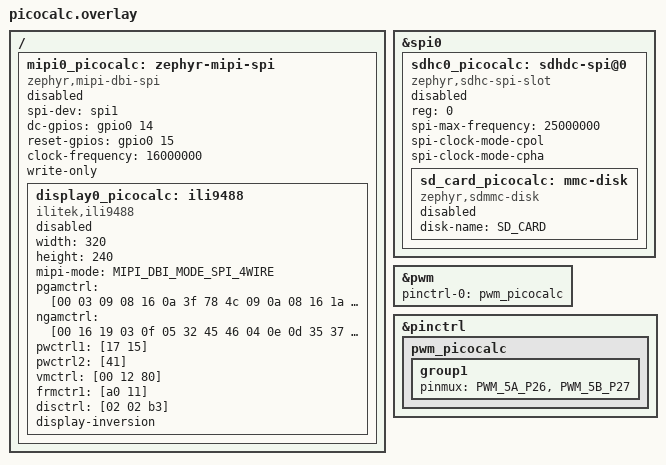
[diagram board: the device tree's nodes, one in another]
/ {
	mipi0_picocalc: zephyr-mipi-spi {
		compatible = "zephyr,mipi-dbi-spi";
		status = "disabled";

		spi-dev = <&spi1>;
		dc-gpios = <&gpio0 14 GPIO_ACTIVE_HIGH>;
		reset-gpios = <&gpio0 15 GPIO_ACTIVE_HIGH>;
		/* run at 16MHz */
		clock-frequency = <16000000>;
		write-only;

		display0_picocalc: ili9488 {
			compatible = "ilitek,ili9488";
			status = "disabled";

			width = <320>;
			height = <240>;
			mipi-mode = "MIPI_DBI_MODE_SPI_4WIRE";
			pgamctrl = [00 03 09 08 16 0a 3f 78 4c 09 0a 08 16 1a 0f];
			ngamctrl = [00 16 19 03 0f 05 32 45 46 04 0e 0d 35 37 0f];
			pwctrl1 = [17 15];
			pwctrl2 = [41];
			vmctrl = [00 12 80];

			frmctr1 = [a0 11];
			disctrl = [02 02 b3];

			display-inversion;
		};
	};
};

&spi0 {
	sdhc0_picocalc: sdhdc-spi@0 {
		compatible = "zephyr,sdhc-spi-slot";
		reg = <0>;
		status = "disabled";
		spi-max-frequency = <25000000>;
		spi-clock-mode-cpol;
		spi-clock-mode-cpha;

		sd_card_picocalc: mmc-disk {
			compatible = "zephyr,sdmmc-disk";
			disk-name = "SD_CARD";
			status = "disabled";
		};
	};
};

&pwm {
	pinctrl-0 = <&pwm_picocalc>;
	pinctrl-names = "default";
};

&pinctrl {
	pwm_picocalc: pwm_picocalc {
		group1 {
			pinmux = <PWM_5A_P26>, <PWM_5B_P27>;
		};
	};
};

